# nrf7140_wificore register map
Vendor: Nordic Semiconductor; Series: nRF71; File version: 1
Registers are 32-bit, read-write, reset 0x0 unless marked. A register's access mark holds for its fields unless they carry their own. Offsets are from the block's base; [hi:lo] are bit positions; lines under a group give offsets from that group; {n}, {i} and the like mark numbered series.

## RPUHPQM
Base 0x480BF000
0x00 UCC_HPQM_SYS group — Unspecified
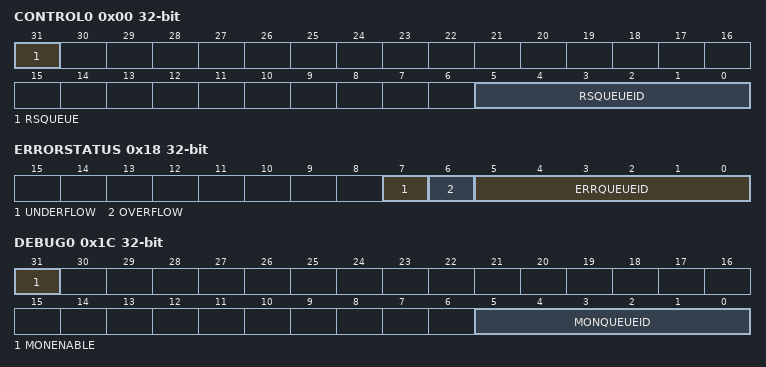
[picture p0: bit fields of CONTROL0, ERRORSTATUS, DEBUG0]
  0x00 CONTROL0 — UCC HPQM SYS CONTROL 0
    [31] RSQUEUE — Writing a 1 to this bit causes all queues to be reset to their default stateWriting a 0 to this bit causes queue RS_QUEUE_ID to be reset to its default stateThis bit is cleared automatically after it has taken effect.
    [5:0] RSQUEUEID — The number of the queue to be reset
  0x04 CONTROL1 reset 0x2 — UCC HPQM SYS CONTROL 1
    [2:0] NUMD256QUEUES — Number of depth-256 queues (0 to 4)
  0x08 CONTROL2 — UCC HPQM SYS CONTROL 2
    [3:0] NUMD128QUEUES — Number of depth-128 queues (0 to 12)
  0x0C CONTROL3 reset 0x4 — UCC HPQM SYS CONTROL 3
    [4:0] NUMD64QUEUES — Number of depth-64 queues (0 to 28)
  0x10 CONTROL4 reset 0x8 — UCC HPQM SYS CONTROL 4
    [5:0] NUMD32QUEUES — Number of depth-32 queues (0 to 60)
  0x14 ERRORCLEAR — UCC HPQM SYS ERROR CLEAR
    [31] ERRFLAGCLR — Writing 1 to this bit clears the UNDERFLOW and OVERFLOW bits in the UCC_HPQM_SYS_ERROR_STATUS register.The QM_ERROR event flag will be clear following this action for either state of ERR_FLAG_EN.This bit is cleared automatically after it has taken effect.
  0x18 ERRORSTATUS ro — UCC HPQM SYS ERROR STATUS
    [7] UNDERFLOW — The least recent queue error was an underflow.This field is read-only
    [6] OVERFLOW — The least recent queue error was an overflow.This field is read-only
    [5:0] ERRQUEUEID — The ID number of the queue which caused the least recent error.This field is read-only
  0x1C DEBUG0 — UCC HPQM SYS DEBUG 0
    [31] MONENABLE
      0=Debug Monitor disabled (default power saving mode); 1=DebugMonitorEnabled
    [5:0] MONQUEUEID — The ID number of the queue to be monitored.Writing any value to this field sets MAX_COUNT to zero.
  0x20 DEBUG1 ro — UCC HPQM SYS DEBUG 1
    [8:0] MONMAXCOUNT — The maximum value of count seen for queue MON_QUEUE_ID since the last write to the QM_SYS_DEBUG_0 register
  0x24 DEBUG2 ro — UCC HPQM SYS DEBUG 2
    [8:0] MONCOUNT — The value of count for the monitored queue MON_QUEUE_ID
  0x28 DEBUG3 ro — UCC HPQM SYS DEBUG 3
    [7:0] MONRDPTR — The value of read_pointer for the monitored queue MON_QUEUE_ID
  0x2C DEBUG4 ro — UCC HPQM SYS DEBUG 4
    [31] MONNOTEMPTY — The NOT_EMPTY flag for the monitored queue MON_QUEUE_ID
  0x30 DEBUG5 ro — UCC HPQM SYS DEBUG 5
    [31] MONNOTFULL — The NOT_FULL flag for the monitored queue MON_QUEUE_ID
  0x40 BUILD0 ro — UCC HPQM SYS BUILD 0
    [1:0] BUILDMAXD256ID — The highest queue ID that can support depth-256 operation in this instance of the Host Port Queue Manager. (0 to 3)
  0x44 BUILD1 ro — UCC HPQM SYS BUILD 1
    [3:0] BUILDMAXD128ID — The highest queue ID that can support depth-128 operation in this instance of the Host Port Queue Manager. (0 to 11)
  0x48 BUILD2 ro — UCC HPQM SYS BUILD 2
    [4:0] BUILDMAXD64ID — The highest queue ID that can support depth-64 operation in this instance of the Host Port Queue Manager. (0 to 27)
  0x4C BUILD3 ro — UCC HPQM SYS BUILD 3
    [5:0] BUILDMAXD32ID — The highest queue ID that can support depth-32 operation in this instance of the Host Port Queue Manager. (0 to 59)
  0x50 BUILD4 ro — UCC HPQM SYS BUILD 4
    [5:0] BUILDMAXQUEUEID — The highest queue ID supported by this instance of the Host Port Queue Manager. (3 to 63)
  0x60 QUEUENOTEMPTYLOW ro — UCC HPQM SYS QUEUE NOT EMPTY LOW
    [31:0] QUEUENOTEMPTYLOW — The lower 32-bits of the NOT_EMPTY flag for all the QUEUES.
  0x64 QUEUENOTEMPTYHIGH ro — UCC HPQM SYS QUEUE NOT EMPTY HIGH
    [31:0] QUEUENOTEMPTYHIGH — The upper 32-bits of the NOT_EMPTY flag for all the QUEUES.
  0x68 QUEUENOTFULLLOW ro reset 0xFFFFFFFF — UCC HPQM SYS QUEUE NOT FULL LOW
    [31:0] QUEUENOTFULLLOW — The lower 32-bits of the NOT_FULL flag for all the QUEUES.
  0x6C QUEUENOTFULLHIGH ro reset 0xFFFFFFFF — UCC HPQM SYS QUEUE NOT FULL HIGH
    [31:0] QUEUENOTFULLHIGH — The upper 32-bits of the NOT_FULL flag for all the QUEUES.
  {0x100+4j} HEAD[{j}] (j=0..63) — Description collection: UCC HPQM SYS HEAD
    [31:0] HEADDATA — Reading this register returns the data item at the head of queue [n].Writing any value to this register causes one item to be popped from the head of queue [n].
  {0x200+4j} TAIL[{j}] (j=0..63) — Description collection: UCC HPQM SYS TAIL
    [31:0] TAILDATA — Reading this register returns the value zero.Data written to this register is added to the tail of queue [n].
